VERSION "2"

NS_ :

BS_:

BU_: MCU EyeQ4

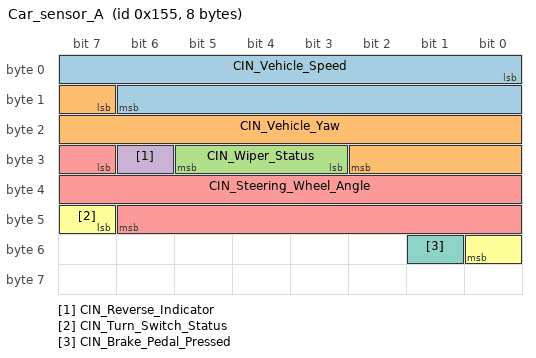
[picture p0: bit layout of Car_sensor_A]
BO_ 341 Car_sensor_A: 8 MCU
 SG_ CIN_Vehicle_Speed : 0|15@1+ (0.015625,0) [0|300] "kph"  EyeQ4
 SG_ CIN_Vehicle_Yaw : 15|12@1+ (0.0625,-128) [-128|127.9375] "deg/s"  EyeQ4
 SG_ CIN_Wiper_Status : 27|3@1+ (1,0) [0|4] "ENUM"  EyeQ4
 SG_ CIN_Reverse_Indicator : 30|1@1+ (1,0) [0|1] "ENUM"  EyeQ4
 SG_ CIN_Steering_Wheel_Angle : 31|16@1- (0.0625,0) [-2048|2047.9375] "deg"  EyeQ4
 SG_ CIN_Turn_Switch_Status : 47|2@1+ (1,0) [0|3] "ENUM"  EyeQ4
 SG_ CIN_Brake_Pedal_Pressed : 49|1@1+ (1,0) [0|1] "ENUM"  EyeQ4

CM_ BO_ 341 "Mandatory!";
CM_ SG_ 341 CIN_Vehicle_Speed "Actual vehicle speed";
CM_ SG_ 341 CIN_Vehicle_Yaw "Positive on right turn";
CM_ SG_ 341 CIN_Wiper_Status "How fast wiper is moving (speed not fully implemented - at the moment, 0 is off and everything else is read as on) 0=OFF 1=ON (LOW) 2=ON (MEDIUM) 3=ON (HIGH) 4=ON (SINGLE WIPE)";
CM_ SG_ 341 CIN_Reverse_Indicator "Indicates negative speed";
CM_ SG_ 341 CIN_Steering_Wheel_Angle "Angle to the right is positive";
CM_ SG_ 341 CIN_Turn_Switch_Status "Status of left right indicator";
CM_ SG_ 341 CIN_Brake_Pedal_Pressed "Indicates whether the pedal is pressed (enum)";
BA_DEF_  "BusType" STRING ;
BA_DEF_ BO_  "GenMsgCycleTime" INT 0 50000;
BA_DEF_DEF_  "BusType" "CAN";
BA_ "GenMsgCycleTime" BO_ 341 10;
VAL_ 341 CIN_Wiper_Status 4 "SINGLE_WIPE" 3 "HIGH" 2 "MEDIUM" 1 "LOW" 0 "OFF" ;
VAL_ 341 CIN_Reverse_Indicator 1 "REVERSE" 0 "FORWARD" ;
VAL_ 341 CIN_Turn_Switch_Status 3 "HAZARD" 2 "RIGHT" 1 "LEFT" 0 "INACTIVE" ;
VAL_ 341 CIN_Brake_Pedal_Pressed 1 "PRESSED" 0 "NOT_PRESSED" ;
